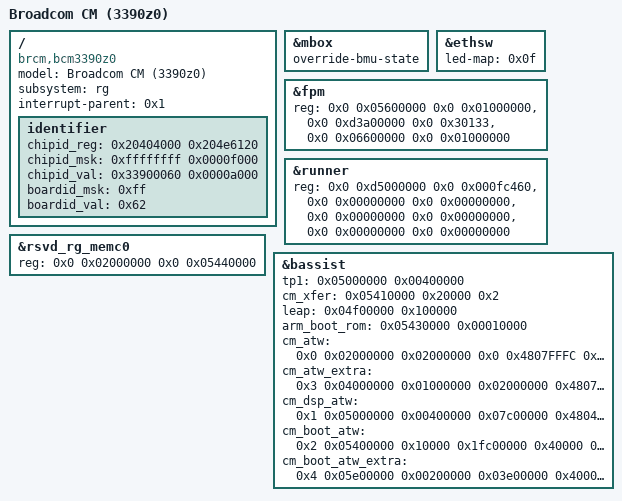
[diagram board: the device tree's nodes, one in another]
/dts-v1/;

/ {
	model = "Broadcom CM (3390z0)";
	compatible = "brcm,bcm3390z0", "brcm,brcmstb";
	subsystem = "rg";
	#address-cells = <0x2>;
	#size-cells = <0x2>;
	interrupt-parent = <0x1>;

	identifier {
		/* register offset */
		chipid_reg = < 0x20404000 0x204e6120 >;
		chipid_msk = < 0xffffffff 0x0000f000 >;
		chipid_val = < 0x33900060 0x0000a000 >;
			     /* DCMS */
		boardid_msk = < 0xff >;
		boardid_val = < 0x62 >;
	};
};

/include/ "rg.3390b0-bolt.dtsi"
/include/ "rg.3390z0-bolt.dtsi"
/include/ "rg.3390-base.dtsi"

/********************************************************************
 * any nodes that appear below are platform specific additions and
 * replacements.
 * The dtc will add or replace any properties in the nodes
 * below to the same nodes that appear in include files above.
 * If the property does not exist in the node above it will be added.
 * If the property does exist it will replace it.
 ********************************************************************/
&mbox {
	override-bmu-state;
};

&ethsw {
	led-map    = <0x0f>;
};

&fpm {
	reg = <0x0 0x05600000 0x0 0x01000000>,	/* Free Pool 0	*/
	      <0x0 0xd3a00000 0x0 0x30133>,	/* Registers	*/
	      <0x0 0x06600000 0x0 0x01000000>;	/* Free Pool 1	*/
};

&runner {
	reg = <0x0 0xd5000000 0x0 0x000fc460>,	/* Registers			*/
	      <0x0 0x00000000 0x0 0x00000000>,	/* Runner Extra Memory 0	*/
	      <0x0 0x00000000 0x0 0x00000000>,	/* Runner Extra Memory 1	*/
	      <0x0 0x00000000 0x0 0x00000000>;	/* Runner NAT Cache		*/
};

&rsvd_rg_memc0 {
	       reg = <0x0 0x02000000 0x0 0x05440000>;
};

&bassist {
	    tp1 = < 0x05000000 0x00400000 >; //start, size
	    cm_xfer = < 0x05410000 0x20000 0x2 >; //start, size, count
	    leap = < 0x04f00000 0x100000>; //start, size
	    arm_boot_rom = <0x05430000 0x00010000>; //start, size
	    cm_atw = < 0x0 0x02000000 0x02000000 0x0 0x4807FFFC 0x0 0x0 0x0 >; //index, start, size, destination, client0-3
	    cm_atw_extra = < 0x3 0x04000000 0x01000000 0x02000000 0x4807FFFC 0x0 0x0 0x0 >; //index, start, size, destination, client0-3
	    cm_dsp_atw = < 0x1 0x05000000 0x00400000 0x07c00000 0x4804FFFC 0x0 0x0 0x0 >; //index, start, size, destination, client0-3
	    cm_boot_atw = < 0x2 0x05400000 0x10000 0x1fc00000 0x40000 0x0 0x0 0x0 >; //index, start, size, destination, client0-3
	    cm_boot_atw_extra = < 0x4 0x05e00000 0x00200000 0x03e00000 0x40000 0x0 0x0 0x0 >; //index, start, size, destination, client0-3
};
